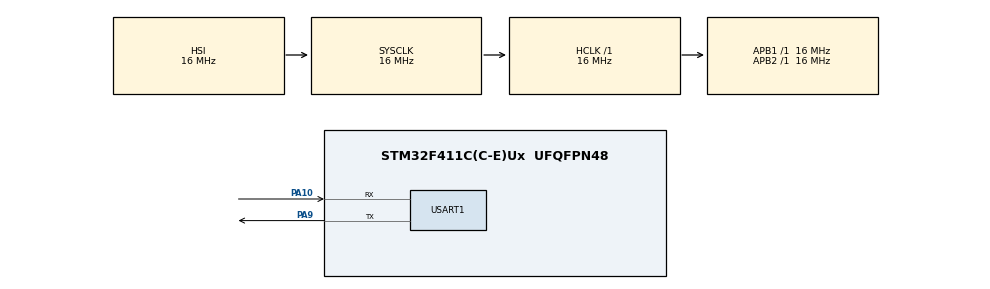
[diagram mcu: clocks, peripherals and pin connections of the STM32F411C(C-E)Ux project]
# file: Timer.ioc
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Mcu.Family=STM32F4
Mcu.Name=STM32F411C(C-E)Ux
Mcu.Package=UFQFPN48
NVIC.PriorityGroup=NVIC_PRIORITYGROUP_4
PA10.Mode=Asynchronous
PA10.Signal=USART1_RX
PA13.Mode=Serial_Wire
PA13.Signal=SYS_JTMS-SWDIO
PA14.Mode=Serial_Wire
PA14.Signal=SYS_JTCK-SWCLK
PA9.Mode=Asynchronous
PA9.Signal=USART1_TX
ProjectManager.HeapSize=0x200
ProjectManager.StackSize=0x400
ProjectManager.TargetToolchain=STM32CubeIDE
RCC.AHBFreq_Value=16000000
RCC.APB1Freq_Value=16000000
RCC.APB2Freq_Value=16000000
RCC.CortexFreq_Value=16000000
RCC.HSE_VALUE=25000000
RCC.HSI_VALUE=16000000
RCC.LSE_VALUE=32768
RCC.SYSCLKFreq_VALUE=16000000
RCC.VCOOutputFreq_Value=192000000
TIM3.Prescaler=255
USART1.VirtualMode=VM_ASYNC
VP_TIM3_VS_ClockSourceINT.Mode=Internal
board=custom

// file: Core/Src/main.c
/* USER CODE BEGIN Header */
/**
  ******************************************************************************
  * @file           : main.c
  * @brief          : Main program body
  ******************************************************************************
  * @attention
  *
  * Copyright (c) 2023 STMicroelectronics.
  * All rights reserved.
  *
  * This software is licensed under terms that can be found in the LICENSE file
  * in the root directory of this software component.
  * If no LICENSE file comes with this software, it is provided AS-IS.
  *
  ******************************************************************************
  */
/* USER CODE END Header */
#include "main.h"
#include <stdio.h>

TIM_HandleTypeDef htim3;

UART_HandleTypeDef huart1;

void SystemClock_Config(void);
static void MX_GPIO_Init(void);
static void MX_TIM3_Init(void);
static void MX_USART1_UART_Init(void);

int main(void)
{
  /* USER CODE BEGIN 1 */
  char uart_buf[50];
  int uart_buf_len;
  uint16_t timer_val;

  HAL_Init();
  SystemClock_Config();

  MX_GPIO_Init();
  MX_TIM3_Init();
  MX_USART1_UART_Init();

  uart_buf_len = sprintf(uart_buf, "Timer Test\r\n");
  HAL_UART_Transmit(&huart1, (uint8_t *)uart_buf, uart_buf_len, 100);
  /* USER CODE END 2 */

  // Start timer
  HAL_TIM_Base_Start(&htim3);

  while (1)
  {
    /* USER CODE END WHILE */
	  timer_val = __HAL_TIM_GET_COUNTER(&htim3);
    /* USER CODE BEGIN 3 */
	  HAL_Delay(0.5);
	  timer_val = __HAL_TIM_GET_COUNTER(&htim3) - timer_val;

	 // Show elapsed time
	  uart_buf_len = sprintf(uart_buf, "%u us\r\n", timer_val);
	  HAL_UART_Transmit(&huart1, (uint8_t *)uart_buf, uart_buf_len, 100);

	  HAL_Delay(500);

  }
  /* USER CODE END 3 */
}

void SystemClock_Config(void)
{
  RCC_OscInitTypeDef RCC_OscInitStruct = {0};
  RCC_ClkInitTypeDef RCC_ClkInitStruct = {0};

  /** Configure the main internal regulator output voltage
  */
  __HAL_RCC_PWR_CLK_ENABLE();
  __HAL_PWR_VOLTAGESCALING_CONFIG(PWR_REGULATOR_VOLTAGE_SCALE1);

  /** Initializes the RCC Oscillators according to the specified parameters
  * in the RCC_OscInitTypeDef structure.
  */
  RCC_OscInitStruct.OscillatorType = RCC_OSCILLATORTYPE_HSI;
  RCC_OscInitStruct.HSIState = RCC_HSI_ON;
  RCC_OscInitStruct.HSICalibrationValue = RCC_HSICALIBRATION_DEFAULT;
  RCC_OscInitStruct.PLL.PLLState = RCC_PLL_NONE;
  if (HAL_RCC_OscConfig(&RCC_OscInitStruct) != HAL_OK)
  {
    Error_Handler();
  }

  /** Initializes the CPU, AHB and APB buses clocks
  */
  RCC_ClkInitStruct.ClockType = RCC_CLOCKTYPE_HCLK|RCC_CLOCKTYPE_SYSCLK
                              |RCC_CLOCKTYPE_PCLK1|RCC_CLOCKTYPE_PCLK2;
  RCC_ClkInitStruct.SYSCLKSource = RCC_SYSCLKSOURCE_HSI;
  RCC_ClkInitStruct.AHBCLKDivider = RCC_SYSCLK_DIV1;
  RCC_ClkInitStruct.APB1CLKDivider = RCC_HCLK_DIV1;
  RCC_ClkInitStruct.APB2CLKDivider = RCC_HCLK_DIV1;

  if (HAL_RCC_ClockConfig(&RCC_ClkInitStruct, FLASH_LATENCY_0) != HAL_OK)
  {
    Error_Handler();
  }
}

static void MX_TIM3_Init(void)
{

  TIM_ClockConfigTypeDef sClockSourceConfig = {0};
  TIM_MasterConfigTypeDef sMasterConfig = {0};

  htim3.Instance = TIM3;
  htim3.Init.Prescaler = 255;
  htim3.Init.CounterMode = TIM_COUNTERMODE_UP;
  htim3.Init.Period = 65535;
  htim3.Init.ClockDivision = TIM_CLOCKDIVISION_DIV1;
  htim3.Init.AutoReloadPreload = TIM_AUTORELOAD_PRELOAD_DISABLE;
  if (HAL_TIM_Base_Init(&htim3) != HAL_OK)
  {
    Error_Handler();
  }
  sClockSourceConfig.ClockSource = TIM_CLOCKSOURCE_INTERNAL;
  if (HAL_TIM_ConfigClockSource(&htim3, &sClockSourceConfig) != HAL_OK)
  {
    Error_Handler();
  }
  sMasterConfig.MasterOutputTrigger = TIM_TRGO_RESET;
  sMasterConfig.MasterSlaveMode = TIM_MASTERSLAVEMODE_DISABLE;
  if (HAL_TIMEx_MasterConfigSynchronization(&htim3, &sMasterConfig) != HAL_OK)
  {
    Error_Handler();
  }

}

static void MX_USART1_UART_Init(void)
{

  huart1.Instance = USART1;
  huart1.Init.BaudRate = 115200;
  huart1.Init.WordLength = UART_WORDLENGTH_8B;
  huart1.Init.StopBits = UART_STOPBITS_1;
  huart1.Init.Parity = UART_PARITY_NONE;
  huart1.Init.Mode = UART_MODE_TX_RX;
  huart1.Init.HwFlowCtl = UART_HWCONTROL_NONE;
  huart1.Init.OverSampling = UART_OVERSAMPLING_16;
  if (HAL_UART_Init(&huart1) != HAL_OK)
  {
    Error_Handler();
  }

}

static void MX_GPIO_Init(void)
{

  /* GPIO Ports Clock Enable */
  __HAL_RCC_GPIOA_CLK_ENABLE();

}

void Error_Handler(void)
{
  __disable_irq();
  while (1)
  {
  }
}
